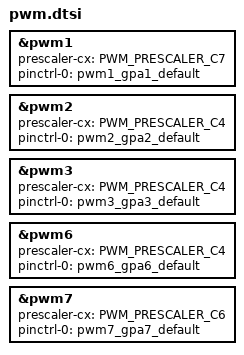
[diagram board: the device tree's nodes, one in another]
/* Copyright 2025 The ChromiumOS Authors
 * Use of this source code is governed by a BSD-style license that can be
 * found in the LICENSE file.
 */

/* Fan - use a separate prescaler for Fan */
&pwm1 {
	status = "okay";
	prescaler-cx = <PWM_PRESCALER_C7>;
	pinctrl-0 = <&pwm1_gpa1_default>;
	pinctrl-names = "default";
};

&pwm2 {
	status = "okay";
	prescaler-cx = <PWM_PRESCALER_C4>;
	pinctrl-0 = <&pwm2_gpa2_default>;
	pinctrl-names = "default";
};

&pwm3 {
	status = "okay";
	prescaler-cx = <PWM_PRESCALER_C4>;
	pinctrl-0 = <&pwm3_gpa3_default>;
	pinctrl-names = "default";
};

&pwm6 {
	status = "okay";
	prescaler-cx = <PWM_PRESCALER_C4>;
	pinctrl-0 = <&pwm6_gpa6_default>;
	pinctrl-names = "default";
};

/* Keyboard backlight - use a prescaler for operation about 324 Hz */
&pwm7 {
	status = "okay";
	prescaler-cx = <PWM_PRESCALER_C6>;
	pinctrl-0 = <&pwm7_gpa7_default>;
	pinctrl-names = "default";
};
